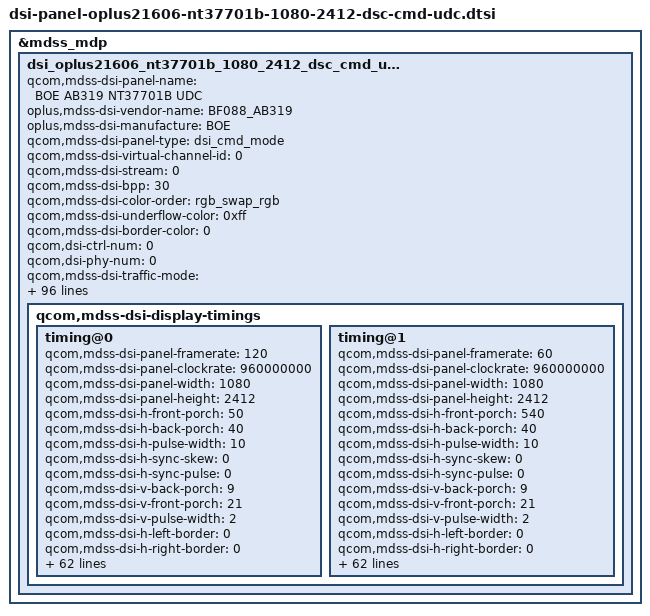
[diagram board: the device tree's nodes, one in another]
&mdss_mdp {
	dsi_oplus21606_nt37701b_1080_2412_dsc_cmd_udc: qcom,mdss_dsi_oplus21606_nt37701b_1080_2412_dsc_cmd_udc {
		qcom,mdss-dsi-panel-name = "BOE AB319 NT37701B UDC";
		oplus,mdss-dsi-vendor-name = "BF088_AB319";
		oplus,mdss-dsi-manufacture = "BOE";
		qcom,mdss-dsi-panel-type = "dsi_cmd_mode";
		qcom,mdss-dsi-virtual-channel-id = <0>;
		qcom,mdss-dsi-stream = <0>;
		qcom,mdss-dsi-bpp = <30>;
		qcom,mdss-dsi-color-order = "rgb_swap_rgb";
		qcom,mdss-dsi-underflow-color = <0xff>;
		qcom,mdss-dsi-border-color = <0>;
		qcom,dsi-ctrl-num = <0>;
		qcom,dsi-phy-num = <0>;
		qcom,mdss-dsi-traffic-mode = "non_burst_sync_event";
		qcom,mdss-dsi-lane-map = "lane_map_0123";
		qcom,mdss-dsi-bllp-eof-power-mode;
		qcom,mdss-dsi-bllp-power-mode;
		qcom,mdss-dsi-lane-0-state;
		qcom,mdss-dsi-lane-1-state;
		qcom,mdss-dsi-lane-2-state;
		qcom,mdss-dsi-lane-3-state;
		qcom,mdss-dsi-dma-trigger = "trigger_sw";
		qcom,mdss-dsi-mdp-trigger = "none";
		qcom,mdss-dsi-reset-sequence = <1 10>, <0 10>, <1 10>;

		qcom,mdss-dsi-te-pin-select = <1>;
		qcom,mdss-dsi-te-dcs-command = <1>;
		qcom,mdss-dsi-te-check-enable;
		qcom,mdss-dsi-te-using-te-pin;
		qcom,mdss-dsi-lp11-init;
		qcom,mdss-dsi-wr-mem-start = <0x2c>;
		qcom,mdss-dsi-wr-mem-continue = <0x3c>;
		qcom,mdss-dsi-panel-hdr-enabled;
		qcom,mdss-dsi-panel-hdr-color-primaries = <15635 16450 34000 16000 13250 34500 7500 3000>;
		qcom,mdss-dsi-panel-peak-brightness = <5400000>;
		qcom,mdss-dsi-panel-blackness-level = <2000>;
		qcom,mdss-pan-physical-width-dimension = <70>;
		qcom,mdss-pan-physical-height-dimension = <153>;
		qcom,esd-check-enabled;
		qcom,mdss-dsi-panel-status-check-mode = "reg_read";
		qcom,mdss-dsi-panel-status-command = [06 01 00 01 05 00 02 0A 00
							06 01 00 01 05 00 02 03 00];
		qcom,mdss-dsi-panel-status-command-state = "dsi_lp_mode";
		qcom,mdss-dsi-panel-status-value = <0x9c 0x01>;
		qcom,mdss-dsi-panel-status-read-length = <1 1>;
		//oplus,esd-debug-enabled;
		//oplus,esd-err-flag-check-enabled;
		oplus,esd-err-flag-gpio = <&tlmm 84 0>;
		oplus,esd-err-trigger-polarity = <1>;
		qcom,dynamic-mode-switch-enabled;
		qcom,dynamic-mode-switch-type = "dynamic-resolution-switch-immediate";
		qcom,mdss-dsi-display-timings {
			timing@0 {
				qcom,mdss-dsi-panel-framerate = <120>;
				qcom,mdss-dsi-panel-clockrate = <960000000>;
				qcom,mdss-dsi-panel-width = <1080>;
				qcom,mdss-dsi-panel-height = <2412>;
				qcom,mdss-dsi-h-front-porch = <50>;
				qcom,mdss-dsi-h-back-porch = <40>;
				qcom,mdss-dsi-h-pulse-width = <10>;
				qcom,mdss-dsi-h-sync-skew = <0>;
				qcom,mdss-dsi-h-sync-pulse = <0>;
				qcom,mdss-dsi-v-back-porch = <9>;
				qcom,mdss-dsi-v-front-porch = <21>;
				qcom,mdss-dsi-v-pulse-width = <2>;
				qcom,mdss-dsi-h-left-border = <0>;
				qcom,mdss-dsi-h-right-border = <0>;
				qcom,mdss-dsi-v-top-border = <0>;
				qcom,mdss-dsi-v-bottom-border = <0>;
				qcom,mdss-dsi-panel-jitter = <0x4 0x1>;

				oplus,fod-on-vblank = <0>;
				oplus,fod-off-vblank = <3>;
				qcom,mdss-dsi-timing-switch-command = [
					//120hz Transition
					39 01 00 00 00 00 06 F0 55 AA 52 08 02
					39 01 00 00 00 00 02 CC 30
					39 01 00 00 00 00 02 6F 03
					39 01 00 00 00 00 02 BF 03
					39 01 00 00 00 00 02 CE 01
					39 01 00 00 1E 00 02 CC 00
					39 01 00 00 00 00 02 2F 02
					39 01 00 00 00 00 06 F0 55 AA 52 08 09
					39 01 00 00 00 00 02 6F 6B
					39 01 00 00 00 00 02 E0 01
				];
				qcom,mdss-dsi-on-command = [
					39 01 00 00 00 00 06 F0 55 AA 52 08 04
					39 01 00 00 00 00 02 35 00
					39 01 00 00 00 00 02 53 20
					39 01 00 00 00 00 05 51 0D BB 0F FE
					39 01 00 00 00 00 03 44 08 F2
					39 01 00 00 00 00 05 2A 00 00 04 37
					39 01 00 00 00 00 05 2B 00 00 09 6B
					39 01 00 00 00 00 02 99 60
					39 01 00 00 00 00 05 FF AA 55 A5 80
					39 01 00 00 00 00 02 6F 1D
					39 01 00 00 00 00 02 F2 05
					39 01 00 00 00 00 02 6F 20
					39 01 00 00 00 00 02 F7 32
					39 01 00 00 00 00 05 FF AA 55 A5 81
					39 01 00 00 00 00 02 6F 0F
					39 01 00 00 00 00 02 FD 01
					39 01 00 00 00 00 02 6F 10
					39 01 00 00 00 00 02 FD 80
					39 01 00 00 00 00 02 82 AE
					39 01 00 00 00 00 02 03 01
					39 01 00 00 00 00 02 90 11
					39 01 00 00 00 00 13 91 AB 2A 00 0C C2 00 01 D8 01 5A 00 0A 08 BB 0A 5F 0C F0
					39 01 00 00 00 00 06 F0 55 AA 52 08 09
					39 01 00 00 00 00 02 D5 80
					39 01 00 00 00 00 06 F0 55 AA 52 08 02
					39 01 00 00 00 00 02 CC 30
					39 01 00 00 00 00 02 6F 03
					39 01 00 00 00 00 02 BF 03
					39 01 00 00 00 00 02 CE 01
					39 01 00 00 1E 00 02 CC 00
					39 01 00 00 00 00 02 2F 02
					39 01 00 00 00 00 03 44 09 20
					39 01 00 00 00 00 06 F0 55 AA 52 08 09
					39 01 00 00 00 00 02 6F 6B
					39 01 00 00 00 00 02 E0 01
					05 01 00 00 79 00 01 11
				];
				qcom,mdss-dsi-off-command= [
					05 01 00 00 0B 00 01 28
					05 01 00 00 79 00 01 10];
				qcom,mdss-dsi-post-on-backlight = [
					/* Display On */
					05 01 00 00 00 00 01 29
				];
				qcom,mdss-dsi-hbm-on-command = [
					//hbm
					39 01 00 00 00 00 03 51 0F FF
				];
				qcom,mdss-dsi-normal-hbm-on-command = [
					//hbm
					39 01 00 00 00 00 03 51 0F FF
				];
				qcom,mdss-dsi-hbm-off-command = [
					39 01 00 00 0A 00 03 51 0D BB
				];
				qcom,mdss-dsi-aod-hbm-on-command = [
					39 01 00 00 00 00 06 F0 55 AA 52 08 00
					15 01 00 00 00 00 02 6F 0D
					39 01 00 00 00 00 02 B5 4F
					39 01 00 00 1E 00 02 65 00
					05 01 00 00 00 00 01 38
					39 01 00 00 00 00 03 51 0F FF
				];
				qcom,mdss-dsi-aod-hbm-off-command = [
					39 01 00 00 00 00 06 F0 55 AA 52 08 00
					15 01 00 00 00 00 02 6F 0D
					39 01 00 00 00 00 02 B5 50
					39 01 00 00 00 00 02 2F 01
					05 01 00 00 1E 00 01 39
					39 01 00 00 00 00 02 65 01
					39 01 00 00 00 00 05 51 00 00 0F FE
					39 01 00 00 00 00 06 F0 55 AA 52 08 00
					39 01 00 00 00 00 02 6F 2E
					39 01 00 00 00 00 03 B4 04 C8
					39 01 00 00 00 00 03 51 0D BB
				];
				qcom,mdss-dsi-aod-high-mode-command = [
					/* AOD 50nit */
					39 01 00 00 00 00 06 F0 55 AA 52 08 00
					15 01 00 00 00 00 02 6F 0D
					39 01 00 00 00 00 02 B5 50
					39 01 00 00 00 00 02 2F 01
					05 01 00 00 1E 00 01 39
					39 01 00 00 00 00 02 65 01
					39 01 00 00 00 00 05 51 00 00 0F FE
					39 01 00 00 00 00 06 F0 55 AA 52 08 00
					39 01 00 00 00 00 02 6F 2E
					39 01 00 00 00 00 03 B4 04 C8
				];
				qcom,mdss-dsi-aod-low-mode-command = [
					/* AOD 10nit */
					39 01 00 00 00 00 06 F0 55 AA 52 08 00
					15 01 00 00 00 00 02 6F 0D
					39 01 00 00 00 00 02 B5 50
					39 01 00 00 00 00 02 2F 01
					05 01 00 00 1E 00 01 39
					39 01 00 00 00 00 02 65 01
					39 01 00 00 00 00 05 51 00 00 0F FE
					39 01 00 00 00 00 06 F0 55 AA 52 08 00
					39 01 00 00 00 00 02 6F 2E
					39 01 00 00 00 00 03 B4 08 9C
				];
				qcom,mdss-dsi-lp1-command = [
					/*AOD on */
					39 01 00 00 00 00 06 F0 55 AA 52 08 00
					15 01 00 00 00 00 02 6F 0D
					39 01 00 00 00 00 02 B5 50
					39 01 00 00 00 00 02 2F 01
					05 01 00 00 1E 00 01 39
					39 01 00 00 00 00 02 65 01
					39 01 00 00 00 00 05 51 00 00 0F FE
					39 01 00 00 00 00 06 F0 55 AA 52 08 00
					39 01 00 00 00 00 02 6F 2E
					39 01 00 00 00 00 03 B4 04 C8
				];
				qcom,mdss-dsi-nolp-command = [
					/* AOD off to normal*/
					39 01 00 00 00 00 06 F0 55 AA 52 08 00
					15 01 00 00 00 00 02 6F 0D
					39 01 00 00 00 00 02 B5 4F
					39 01 00 00 1E 00 02 65 00
					05 01 00 00 00 00 01 38
				];
				//qcom,mdss-dsi-seed-off-command = [
				//	/* CRC OFF */
				//	39 01 00 00 00 00 03 F0 5A 5A
 				//	15 01 00 00 00 00 02 5D 00
 				//	15 01 00 00 00 00 02 62 01
 				//	39 01 00 00 00 00 03 F0 A5 A5
				//];
				//qcom,mdss-dsi-seed-3-command = [
				//	39 01 00 00 00 00 03 F0 5A 5A
				//	39 01 00 00 00 00 03 B0 03 8F
				//	39 01 00 00 00 00 02 8F 25
				//	39 01 00 00 00 00 03 B0 28 F2
				//	39 01 00 00 00 00 02 F2 CE
				//	39 01 00 00 00 00 04 B0 01 18 68
				//	39 01 00 00 00 00 0F 68 E2 1A 1A 1A 82 04 F0 80 00 00 00 00 FF 00
				//	39 01 00 00 00 00 04 B0 00 28 F2
				//	39 01 00 00 00 00 02 F2 C6
				//	39 01 00 00 00 00 03 F0 A5 A5
				//	39 01 00 00 00 00 03 F0 5A 5A
				//	39 01 00 00 00 00 04 72 2C 21 00
				//	39 01 00 00 00 00 02 F8 00
				//	39 01 00 00 00 00 02 5D 06
				//	39 01 00 00 00 00 02 62 00
				//	39 01 00 00 00 00 03 B0 01 62
				//	39 01 00 00 00 00 16 62 D3 01 00 19 Fd 00 0B 04 E2 21 E5 E4 de 06 Ec FA FD 01 FF FF FF
				//	39 01 00 00 18 00 04 72 2C 01 00
				//	39 01 00 00 00 00 03 F0 A5 A5
				//];
				//qcom,mdss-dsi-seed-2-command = [
				//	39 01 00 00 00 00 03 F0 5A 5A
				//	39 01 00 00 00 00 03 B0 03 8F
				//	39 01 00 00 00 00 02 8F 05
				//	39 01 00 00 00 00 03 B0 28 F2
				//	39 01 00 00 00 00 02 F2 CE
				//	39 01 00 00 00 00 04 B0 01 18 68
				//	39 01 00 00 00 00 0F 68 E2 1A 1A 1A 82 04 F0 80 00 00 00 00 FF 00
				//	39 01 00 00 00 00 04 B0 00 28 F2
				//	39 01 00 00 00 00 02 F2 C6
				//	39 01 00 00 00 00 03 F0 A5 A5
				//	39 01 00 00 00 00 03 F0 5A 5A
				//	39 01 00 00 00 00 04 72 2C 21 00
				//	39 01 00 00 00 00 02 F8 00
				//	39 01 00 00 00 00 02 5D 06
				//	39 01 00 00 00 00 02 62 00
				//	39 01 00 00 00 00 03 B0 01 62
				//	39 01 00 00 00 00 16 62 FF 00 00 00 FF 00 00 00 FF 00 FF FF FF 00 FF FF FF 00 FF FF FF
				//	39 01 00 00 18 00 04 72 2C 01 00
				//	39 01 00 00 00 00 03 F0 A5 A5
				//];
				//qcom,mdss-dsi-seed-1-command = [
				//	39 01 00 00 00 00 03 F0 5A 5A
				//	39 01 00 00 00 00 03 B0 03 8F
				//	39 01 00 00 00 00 02 8F 25
				//	39 01 00 00 00 00 03 B0 28 F2
				//	39 01 00 00 00 00 02 F2 CE
				//	39 01 00 00 00 00 04 B0 01 18 68
				//	39 01 00 00 00 00 0F 68 E2 1A 1A 1A 82 04 F0 80 00 00 00 00 FF 00
				//	39 01 00 00 00 00 04 B0 00 28 F2
				//	39 01 00 00 00 00 02 F2 C6
				//	39 01 00 00 00 00 03 F0 A5 A5
				//	39 01 00 00 00 00 03 F0 5A 5A
				//	39 01 00 00 00 00 04 72 2C 21 00
				//	39 01 00 00 00 00 02 F8 00
				//	39 01 00 00 00 00 02 5D 06
				//	39 01 00 00 00 00 02 62 00
				//	39 01 00 00 00 00 03 B0 01 62
				//	39 01 00 00 00 00 16 62 D3 01 00 19 Fd 00 0B 04 E2 21 E5 E4 de 06 Ec FA FD 01 FF FF FF
				//	39 01 00 00 18 00 04 72 2C 01 00
				//	39 01 00 00 00 00 03 F0 A5 A5
				//];
				//qcom,mdss-dsi-seed-0-command = [
				//	39 01 00 00 00 00 03 F0 5A 5A
				//	39 01 00 00 00 00 03 B0 03 8F
				//	39 01 00 00 00 00 02 8F 05
				//	39 01 00 00 00 00 03 B0 28 F2
				//	39 01 00 00 00 00 02 F2 CE
				//	39 01 00 00 00 00 04 B0 01 18 68
				//	39 01 00 00 00 00 0F 68 E2 1A 1A 1A 82 04 F0 80 00 00 00 00 FF 90
				//	39 01 00 00 00 00 04 B0 00 28 F2
				//	39 01 00 00 00 00 02 F2 C6
				//	39 01 00 00 00 00 03 F0 A5 A5
				//	39 01 00 00 00 00 03 F0 5A 5A
				//	39 01 00 00 00 00 04 72 2C 21 00
				//	39 01 00 00 00 00 02 F8 00
				//	39 01 00 00 00 00 02 5D 06
				//	39 01 00 00 00 00 02 62 00
				//	39 01 00 00 00 00 03 B0 01 62
				//	39 01 00 00 00 00 16 62 E5 02 00 1E F2 04 0B 06 E5 28 F3 F7 F8 08 FF EA F4 02 FF FF FF
				//	39 01 00 00 18 00 04 72 2C 01 00
				//	39 01 00 00 00 00 03 F0 A5 A5
				//];
				qcom,mdss-dsi-hbm-enter-switch-command = [
					39 01 00 00 00 00 03 51 0D BB
				];
				qcom,mdss-dsi-hbm-exit-switch-command = [
					39 01 00 00 00 00 03 51 0D BB
				];
				qcom,mdss-dsi-osc-clk-mode0-command = [
					/*OSC 415 + 180.3*/
					39 01 00 00 00 00 03 F0 5A 5A
					39 01 00 00 00 00 03 FC 5A 5A
					39 01 00 00 00 00 03 B0 2A C5
					39 01 00 00 00 00 05 C5 0D 10 80 45
					39 01 00 00 00 00 03 B0 2E C5
					39 01 00 00 00 00 03 C5 6F 39
					39 01 00 00 00 00 03 F0 A5 A5
					39 01 00 00 00 00 03 FC A5 A5
				];
				qcom,mdss-dsi-osc-clk-mode1-command = [
					/*OSC 415 + 182.3*/
					39 01 00 00 00 00 03 F0 5A 5A
					39 01 00 00 00 00 03 FC 5A 5A
					39 01 00 00 00 00 03 B0 2A C5
					39 01 00 00 00 00 05 C5 0D 10 80 45
					39 01 00 00 00 00 03 B0 2E C5
					39 01 00 00 00 00 03 C5 70 74
					39 01 00 00 00 00 03 F0 A5 A5
					39 01 00 00 00 00 03 FC A5 A5
				];
				qcom,mdss-dsi-timing-switch-command-state = "dsi_hs_mode";
				qcom,mdss-dsi-on-command-state = "dsi_lp_mode";
				qcom,mdss-dsi-off-command-state = "dsi_hs_mode";
				qcom,mdss-dsi-hbm-on-command-state = "dsi_hs_mode";
				qcom,mdss-dsi-hbm-off-command-state = "dsi_hs_mode";
				qcom,mdss-dsi-osc-clk-mode0-command-state = "dsi_hs_mode";
				qcom,mdss-dsi-osc-clk-mode1-command-state = "dsi_hs_mode";
				//qcom,mdss-dsi-seed-0-command-state = "dsi_hs_mode";
				//qcom,mdss-dsi-seed-1-command-state = "dsi_hs_mode";
				//qcom,mdss-dsi-seed-2-command-state = "dsi_hs_mode";
				//qcom,mdss-dsi-seed-3-command-state = "dsi_hs_mode";
				//qcom,mdss-dsi-seed-off-command-state = "dsi_hs_mode";
				qcom,compression-mode = "dsc";
				qcom,mdss-dsc-slice-height = <12>;
				qcom,mdss-dsc-slice-width = <540>;
				qcom,mdss-dsc-slice-per-pkt = <2>;
				qcom,mdss-dsc-bit-per-component = <10>;
				qcom,mdss-dsc-bit-per-pixel = <10>;
				qcom,mdss-dsc-block-prediction-enable;
			};

			timing@1 {
				qcom,mdss-dsi-panel-framerate = <60>;
				qcom,mdss-dsi-panel-clockrate = <960000000>;
				qcom,mdss-dsi-panel-width = <1080>;
				qcom,mdss-dsi-panel-height = <2412>;
				qcom,mdss-dsi-h-front-porch = <540>;
				qcom,mdss-dsi-h-back-porch = <40>;
				qcom,mdss-dsi-h-pulse-width = <10>;
				qcom,mdss-dsi-h-sync-skew = <0>;
				qcom,mdss-dsi-h-sync-pulse = <0>;
				qcom,mdss-dsi-v-back-porch = <9>;
				qcom,mdss-dsi-v-front-porch = <21>;
				qcom,mdss-dsi-v-pulse-width = <2>;
				qcom,mdss-dsi-h-left-border = <0>;
				qcom,mdss-dsi-h-right-border = <0>;
				qcom,mdss-dsi-v-top-border = <0>;
				qcom,mdss-dsi-v-bottom-border = <0>;
				qcom,mdss-dsi-panel-jitter = <0x4 0x1>;

				oplus,fod-on-vblank = <0>;
				oplus,fod-off-vblank = <3>;
				qcom,mdss-dsi-timing-switch-command = [
					//60hz Transition
					39 01 00 00 00 00 06 F0 55 AA 52 08 02
					39 01 00 00 00 00 02 CC 30
					39 01 00 00 00 00 02 6F 03
					39 01 00 00 00 00 02 BF 02
					39 01 00 00 00 00 02 CE 01
					39 01 00 00 1E 00 02 CC 00
					39 01 00 00 00 00 02 2F 01
					39 01 00 00 00 00 06 F0 55 AA 52 08 09
					39 01 00 00 00 00 02 6F 6B
					39 01 00 00 00 00 02 E0 00
				];
				qcom,mdss-dsi-on-command = [
					39 01 00 00 00 00 06 F0 55 AA 52 08 04
					39 01 00 00 00 00 02 35 00
					39 01 00 00 00 00 02 53 20
					39 01 00 00 00 00 05 51 0D BB 0F FE
					39 01 00 00 00 00 03 44 08 F2
					39 01 00 00 00 00 05 2A 00 00 04 37
					39 01 00 00 00 00 05 2B 00 00 09 6B
					39 01 00 00 00 00 02 99 60
					39 01 00 00 00 00 05 FF AA 55 A5 80
					39 01 00 00 00 00 02 6F 1D
					39 01 00 00 00 00 02 F2 05
					39 01 00 00 00 00 02 6F 20
					39 01 00 00 00 00 02 F7 32
					39 01 00 00 00 00 05 FF AA 55 A5 81
					39 01 00 00 00 00 02 6F 0F
					39 01 00 00 00 00 02 FD 01
					39 01 00 00 00 00 02 6F 10
					39 01 00 00 00 00 02 FD 80
					39 01 00 00 00 00 02 82 AE
					39 01 00 00 00 00 02 03 01
					39 01 00 00 00 00 02 90 11
					39 01 00 00 00 00 13 91 AB 2A 00 0C C2 00 01 D8 01 5A 00 0A 08 BB 0A 5F 0C F0
					39 01 00 00 00 00 06 F0 55 AA 52 08 09
					39 01 00 00 00 00 02 D5 80
					39 01 00 00 00 00 06 F0 55 AA 52 08 02
					39 01 00 00 00 00 02 CC 30
					39 01 00 00 00 00 02 6F 03
					39 01 00 00 00 00 02 BF 02
					39 01 00 00 00 00 02 CE 01
					39 01 00 00 1E 00 02 CC 00
					39 01 00 00 00 00 02 2F 01
					39 01 00 00 00 00 03 44 09 20
					39 01 00 00 00 00 06 F0 55 AA 52 08 09
					39 01 00 00 00 00 02 6F 6B
					39 01 00 00 00 00 02 E0 00
					05 01 00 00 79 00 01 11
				];
				qcom,mdss-dsi-off-command= [
					05 01 00 00 0B 00 01 28
					05 01 00 00 79 00 01 10];
				qcom,mdss-dsi-post-on-backlight = [
					/* Display On */
					05 01 00 00 00 00 01 29
				];
				qcom,mdss-dsi-hbm-on-command = [
					//hbm
					39 01 00 00 00 00 03 51 0F FF
				];
				qcom,mdss-dsi-normal-hbm-on-command = [
					//hbm
					39 01 00 00 00 00 03 51 0F FF
				];
				qcom,mdss-dsi-hbm-off-command = [
					39 01 00 00 0A 00 03 51 0D BB
				];
				qcom,mdss-dsi-aod-hbm-on-command = [
					39 01 00 00 00 00 06 F0 55 AA 52 08 00
					15 01 00 00 00 00 02 6F 0D
					39 01 00 00 00 00 02 B5 4F
					39 01 00 00 1E 00 02 65 00
					05 01 00 00 00 00 01 38
					39 01 00 00 00 00 03 51 0F FF
				];
				qcom,mdss-dsi-aod-hbm-off-command = [
					39 01 00 00 00 00 06 F0 55 AA 52 08 00
					15 01 00 00 00 00 02 6F 0D
					39 01 00 00 00 00 02 B5 50
					39 01 00 00 00 00 02 2F 01
					05 01 00 00 1E 00 01 39
					39 01 00 00 00 00 02 65 01
					39 01 00 00 00 00 05 51 00 00 0F FE
					39 01 00 00 00 00 06 F0 55 AA 52 08 00
					39 01 00 00 00 00 02 6F 2E
					39 01 00 00 00 00 03 B4 04 C8
					39 01 00 00 00 00 03 51 0D BB
				];
				qcom,mdss-dsi-aod-high-mode-command = [
					/* AOD 50nit */
					39 01 00 00 00 00 06 F0 55 AA 52 08 00
					15 01 00 00 00 00 02 6F 0D
					39 01 00 00 00 00 02 B5 50
					39 01 00 00 00 00 02 2F 01
					05 01 00 00 1E 00 01 39
					39 01 00 00 00 00 02 65 01
					39 01 00 00 00 00 05 51 00 00 0F FE
					39 01 00 00 00 00 06 F0 55 AA 52 08 00
					39 01 00 00 00 00 02 6F 2E
					39 01 00 00 00 00 03 B4 04 C8
				];
				qcom,mdss-dsi-aod-low-mode-command = [
					/* AOD 10nit */
					39 01 00 00 00 00 06 F0 55 AA 52 08 00
					15 01 00 00 00 00 02 6F 0D
					39 01 00 00 00 00 02 B5 50
					39 01 00 00 00 00 02 2F 01
					05 01 00 00 1E 00 01 39
					39 01 00 00 00 00 02 65 01
					39 01 00 00 00 00 05 51 00 00 0F FE
					39 01 00 00 00 00 06 F0 55 AA 52 08 00
					39 01 00 00 00 00 02 6F 2E
					39 01 00 00 00 00 03 B4 08 9C
				];
				qcom,mdss-dsi-lp1-command = [
					/*AOD on */
					39 01 00 00 00 00 06 F0 55 AA 52 08 00
					15 01 00 00 00 00 02 6F 0D
					39 01 00 00 00 00 02 B5 50
					39 01 00 00 00 00 02 2F 01
					05 01 00 00 1E 00 01 39
					39 01 00 00 00 00 02 65 01
					39 01 00 00 00 00 05 51 00 00 0F FE
					39 01 00 00 00 00 06 F0 55 AA 52 08 00
					39 01 00 00 00 00 02 6F 2E
					39 01 00 00 00 00 03 B4 04 C8
				];
				qcom,mdss-dsi-nolp-command = [
					/* AOD off to normal*/
					39 01 00 00 00 00 06 F0 55 AA 52 08 00
					15 01 00 00 00 00 02 6F 0D
					39 01 00 00 00 00 02 B5 4F
					39 01 00 00 1E 00 02 65 00
					05 01 00 00 00 00 01 38
				];
				//qcom,mdss-dsi-seed-off-command = [
				//	/* CRC OFF */
				//	39 01 00 00 00 00 03 F0 5A 5A
				//	15 01 00 00 00 00 02 5D 00
				//	15 01 00 00 00 00 02 62 01
				//	39 01 00 00 00 00 03 F0 A5 A5
				//];
				//qcom,mdss-dsi-seed-3-command = [
				//	39 01 00 00 00 00 03 F0 5A 5A
				//	39 01 00 00 00 00 03 B0 03 8F
				//	39 01 00 00 00 00 02 8F 25
				//	39 01 00 00 00 00 03 B0 28 F2
				//	39 01 00 00 00 00 02 F2 CE
				//	39 01 00 00 00 00 04 B0 01 18 68
				//	39 01 00 00 00 00 0F 68 E2 1A 1A 1A 82 04 F0 80 00 00 00 00 FF 00
				//	39 01 00 00 00 00 04 B0 00 28 F2
				//	39 01 00 00 00 00 02 F2 C6
				//	39 01 00 00 00 00 03 F0 A5 A5
				//	39 01 00 00 00 00 03 F0 5A 5A
				//	39 01 00 00 00 00 04 72 2C 21 00
				//	39 01 00 00 00 00 02 F8 00
				//	39 01 00 00 00 00 02 5D 06
				//	39 01 00 00 00 00 02 62 00
				//	39 01 00 00 00 00 03 B0 01 62
				//	39 01 00 00 00 00 16 62 D3 01 00 19 Fd 00 0B 04 E2 21 E5 E4 de 06 Ec FA FD 01 FF FF FF
				//	39 01 00 00 18 00 04 72 2C 01 00
				//	39 01 00 00 00 00 03 F0 A5 A5
				//];
				//qcom,mdss-dsi-seed-2-command = [
				//	39 01 00 00 00 00 03 F0 5A 5A
				//	39 01 00 00 00 00 03 B0 03 8F
				//	39 01 00 00 00 00 02 8F 05
				//	39 01 00 00 00 00 03 B0 28 F2
				//	39 01 00 00 00 00 02 F2 CE
				//	39 01 00 00 00 00 04 B0 01 18 68
				//	39 01 00 00 00 00 0F 68 E2 1A 1A 1A 82 04 F0 80 00 00 00 00 FF 00
				//	39 01 00 00 00 00 04 B0 00 28 F2
				//	39 01 00 00 00 00 02 F2 C6
				//	39 01 00 00 00 00 03 F0 A5 A5
				//	39 01 00 00 00 00 03 F0 5A 5A
				//	39 01 00 00 00 00 04 72 2C 21 00
				//	39 01 00 00 00 00 02 F8 00
				//	39 01 00 00 00 00 02 5D 06
				//	39 01 00 00 00 00 02 62 00
				//	39 01 00 00 00 00 03 B0 01 62
				//	39 01 00 00 00 00 16 62 FF 00 00 00 FF 00 00 00 FF 00 FF FF FF 00 FF FF FF 00 FF FF FF
				//	39 01 00 00 18 00 04 72 2C 01 00
				//	39 01 00 00 00 00 03 F0 A5 A5
				//];
				//qcom,mdss-dsi-seed-1-command = [
				//	39 01 00 00 00 00 03 F0 5A 5A
				//	39 01 00 00 00 00 03 B0 03 8F
				//	39 01 00 00 00 00 02 8F 25
				//	39 01 00 00 00 00 03 B0 28 F2
				//	39 01 00 00 00 00 02 F2 CE
				//	39 01 00 00 00 00 04 B0 01 18 68
				//	39 01 00 00 00 00 0F 68 E2 1A 1A 1A 82 04 F0 80 00 00 00 00 FF 00
				//	39 01 00 00 00 00 04 B0 00 28 F2
				//	39 01 00 00 00 00 02 F2 C6
				//	39 01 00 00 00 00 03 F0 A5 A5
				//	39 01 00 00 00 00 03 F0 5A 5A
				//	39 01 00 00 00 00 04 72 2C 21 00
				//	39 01 00 00 00 00 02 F8 00
				//	39 01 00 00 00 00 02 5D 06
				//	39 01 00 00 00 00 02 62 00
				//	39 01 00 00 00 00 03 B0 01 62
				//	39 01 00 00 00 00 16 62 D3 01 00 19 Fd 00 0B 04 E2 21 E5 E4 de 06 Ec FA FD 01 FF FF FF
				//	39 01 00 00 18 00 04 72 2C 01 00
				//	39 01 00 00 00 00 03 F0 A5 A5
				//];
				//qcom,mdss-dsi-seed-0-command = [
				//	39 01 00 00 00 00 03 F0 5A 5A
				//	39 01 00 00 00 00 03 B0 03 8F
				//	39 01 00 00 00 00 02 8F 05
				//	39 01 00 00 00 00 03 B0 28 F2
				//	39 01 00 00 00 00 02 F2 CE
				//	39 01 00 00 00 00 04 B0 01 18 68
				//	39 01 00 00 00 00 0F 68 E2 1A 1A 1A 82 04 F0 80 00 00 00 00 FF 90
				//	39 01 00 00 00 00 04 B0 00 28 F2
				//	39 01 00 00 00 00 02 F2 C6
				//	39 01 00 00 00 00 03 F0 A5 A5
				//	39 01 00 00 00 00 03 F0 5A 5A
				//	39 01 00 00 00 00 04 72 2C 21 00
				//	39 01 00 00 00 00 02 F8 00
				//	39 01 00 00 00 00 02 5D 06
				//	39 01 00 00 00 00 02 62 00
				//	39 01 00 00 00 00 03 B0 01 62
				//	39 01 00 00 00 00 16 62 E5 02 00 1E F2 04 0B 06 E5 28 F3 F7 F8 08 FF EA F4 02 FF FF FF
				//	39 01 00 00 18 00 04 72 2C 01 00
				//	39 01 00 00 00 00 03 F0 A5 A5
				//];
				qcom,mdss-dsi-hbm-enter-switch-command = [
					39 01 00 00 00 00 03 51 0D BB
				];
				qcom,mdss-dsi-hbm-exit-switch-command = [
					39 01 00 00 00 00 03 51 0D BB
				];
				qcom,mdss-dsi-osc-clk-mode0-command = [
					/*OSC 415 + 180.3*/
					39 01 00 00 00 00 03 F0 5A 5A
					39 01 00 00 00 00 03 FC 5A 5A
					39 01 00 00 00 00 03 B0 2A C5
					39 01 00 00 00 00 05 C5 0D 10 80 45
					39 01 00 00 00 00 03 B0 2E C5
					39 01 00 00 00 00 03 C5 6F 39
					39 01 00 00 00 00 03 F0 A5 A5
					39 01 00 00 00 00 03 FC A5 A5
				];
				qcom,mdss-dsi-osc-clk-mode1-command = [
					/*OSC 415 + 182.3*/
					39 01 00 00 00 00 03 F0 5A 5A
					39 01 00 00 00 00 03 FC 5A 5A
					39 01 00 00 00 00 03 B0 2A C5
					39 01 00 00 00 00 05 C5 0D 10 80 45
					39 01 00 00 00 00 03 B0 2E C5
					39 01 00 00 00 00 03 C5 70 74
					39 01 00 00 00 00 03 F0 A5 A5
					39 01 00 00 00 00 03 FC A5 A5
				];

				qcom,mdss-dsi-timing-switch-command-state = "dsi_hs_mode";
				qcom,mdss-dsi-on-command-state = "dsi_lp_mode";
				qcom,mdss-dsi-off-command-state = "dsi_hs_mode";
				qcom,mdss-dsi-hbm-on-command-state = "dsi_hs_mode";
				qcom,mdss-dsi-hbm-off-command-state = "dsi_hs_mode";
				qcom,mdss-dsi-osc-clk-mode0-command-state = "dsi_hs_mode";
				qcom,mdss-dsi-osc-clk-mode1-command-state = "dsi_hs_mode";
				//qcom,mdss-dsi-seed-0-command-state = "dsi_hs_mode";
				//qcom,mdss-dsi-seed-1-command-state = "dsi_hs_mode";
				//qcom,mdss-dsi-seed-2-command-state = "dsi_hs_mode";
				//qcom,mdss-dsi-seed-3-command-state = "dsi_hs_mode";
				//qcom,mdss-dsi-seed-off-command-state = "dsi_hs_mode";
				qcom,compression-mode = "dsc";
				qcom,mdss-dsc-slice-height = <12>;
				qcom,mdss-dsc-slice-width = <540>;
				qcom,mdss-dsc-slice-per-pkt = <2>;
				qcom,mdss-dsc-bit-per-component = <10>;
				qcom,mdss-dsc-bit-per-pixel = <10>;
				qcom,mdss-dsc-block-prediction-enable;
			};
		};
	};
};



&dsi_oplus21606_nt37701b_1080_2412_dsc_cmd_udc {
	qcom,panel-supply-entries = <&dsi_panel_oplus_jennie_pwr_supply>;
	qcom,mdss-dsi-panel-controller = <&mdss_dsi0>;
	qcom,mdss-dsi-bl-pmic-control-type = "bl_ctrl_dcs";
	qcom,mdss-dsi-bl-min-level = <1>;
	qcom,mdss-dsi-bl-normal-max-level = <3515>;
	qcom,mdss-dsi-bl-max-level = <4095>;
	qcom,mdss-brightness-normal-max-level = <3515>;
	qcom,mdss-brightness-max-level = <4095>;
	qcom,mdss-brightness-default-level = <400>;
	qcom,mdss-dsi-bl-inverted-dbv;
	qcom,platform-te-gpio = <&tlmm 86 0>;
	qcom,platform-reset-gpio = <&tlmm 3 0>;
	qcom,platform-panel-vddr-aod-en-gpio = <&tlmm 90 0>;
	qcom,mdss-dsi-reset-sequence = <1 3>, <0 11>, <1 11>;
	qcom,ulps-enabled;
	//qcom,dsi-dyn-clk-enable;
	//qcom,dsi-dyn-clk-list = <800000000 830000000>;
	qcom,dsi-select-clocks = "pll_byte_clk0", "pll_dsi_clk0";
	//oplus,osc-support;
	oplus,mdss-dsi-osc-clk-mode0-rate = <180300>;
	oplus,mdss-dsi-osc-clk-mode1-rate = <182300>;
	qcom,mdss-dsi-dc-backlight-level = <1100>;
	oplus,apollo-sync-brightness-level = <711>;
	//oplus,dc_apollo_sync_enable;
	oplus,dc-apollo-backlight-sync-level = <1100>;
	oplus,dc-apollo-backlight-sync-level-pcc-max = <32760>;
	oplus,dc-apollo-backlight-sync-level-pcc-min = <21600>;
	/* aod/fod config */
	oplus,ofp-fp-type = <0x08>;
	oplus,ofp-config = <01>;
	oplus,dsi-ofp-brightness = <0 255>,
				<4 238>,
				<60 0xec>,
				<90 0xeb>,
				<140 0xea>,
				<200 0xe8>,
				<300 0xe4>,
				<458 0xe0>,
				<605 0xdb>,
				<743 0xcf>,
				<912 0xc8>,
				<1062 0xbf>,
				<1187 0xb6>,
				<1393 0xa0>,
				<1611 0x9b>,
				<1787 0x92>,
				<2000 0x8b>,
				<2200 0x80>,
				<2400 0x70>,
				<2600 0x60>,
				<2800 0x50>,
				<3000 0x4A>,
				<3200 0x40>,
				<3400 0x36>,
				<3515 0x2e>;

	oplus,dsi-dc-brightness = <0 255>,
			<1 255>,
			<4 248>,
			<8 247>,
			<35 245>,
			<105 243>,
			<195 240>,
			<235 238>,
			<305 233>,
			<400 225>,
			<500 215>,
			<580 205>,
			<591 195>,
			<660 175>,
			<720 155>,
			<780 135>,
			<825 115>,
			<865 95>,
			<900 76>,
			<963 55>,
			<1000 38>,
			<1050 18>,
			<1100 0>;
/*
	oplus,dsi-brightness-remapping = <4    4>,
			<5    5>,
			<6    6>,
			<7    7>,
			<10   10>,
			<244  19>,
			<373  49>,
			<493  90>,
			<585  130>,
			<663  171>,
			<731  212>,
			<792  253>,
			<847  294>,
			<899  335>,
			<948  376>,
			<993  417>,
			<1036 458>,
			<1078 499>,
			<1117 540>,
			<1155 581>,
			<1191 622>,
			<1226 663>,
			<1260 704>,
			<1293 745>,
			<1325 786>,
			<1356 826>,
			<1386 867>,
			<1415 908>,
			<1444 949>,
			<1472 990>,
			<1499 1031>,
			<1526 1072>,
			<1552 1113>,
			<1578 1154>,
			<1603 1195>,
			<1628 1236>,
			<1652 1277>,
			<1676 1318>,
			<1699 1359>,
			<1722 1400>,
			<1745 1441>,
			<1767 1482>,
			<1789 1522>,
			<1811 1563>,
			<1833 1604>,
			<1854 1645>,
			<1875 1686>,
			<1895 1727>,
			<1915 1768>,
			<1935 1809>,
			<1955 1850>,
			<1975 1891>,
			<1994 1932>,
			<2013 1973>,
			<2032 2014>,
			<2043 2038>,
			<2045 2042>,
			<2047 2047>,
			<4095 4095>;
*/
	qcom,mdss-dsi-display-timings {
		timing@0 {
				qcom,mdss-dsi-panel-phy-timings = [00 21 08 08 19 22 09 08 09 02 04 00 1C 0D];
				qcom,display-topology = <1 1 1>,<2 2 1>;
				qcom,default-topology-index = <0>;
		};
		timing@1 {
				qcom,mdss-dsi-panel-phy-timings = [00 21 08 08 19 22 09 08 09 02 04 00 1C 0D];
				qcom,display-topology = <1 1 1>,<2 2 1>;
				qcom,default-topology-index = <0>;
		};
	};
};

&dsi_oplus21606_nt37701b_1080_2412_dsc_cmd_udc {
	oplus,color_vivid_status;
	oplus,color_srgb_status;
	oplus,color_softiris_status;
	oplus,color_dual_brightness_status;
	//oplus,color_oplus_calibrate_status;
	//oplus,apollo_backlight_enable;
	//oplus,color_srgb_status;
	oplus,dsi-serial-number-enabled;
	//oplus,dsi-serial-number-lock;
	oplus,dsi-serial-number-reg= <0xA3>;
	oplus,dsi-serial-number-index= <11>;
	oplus,dsi-serial-number-read-count= <18>;
	oplus,dsi-bl-normal-max-level = <3515>;
	oplus,dsi-brightness-normal-max-level = <3515>;
};

&dsi_oplus21606_nt37701b_1080_2412_dsc_cmd_udc {
	qcom,panel_voltage_vddi_name = "vddio";
	qcom,panel_voltage_vddi = <0 1800000 1850000 1950000>;
	qcom,panel_voltage_vddr_name = "vddio";
	qcom,panel_voltage_vddr = <1 1800000 1850000 1950000>;
};
